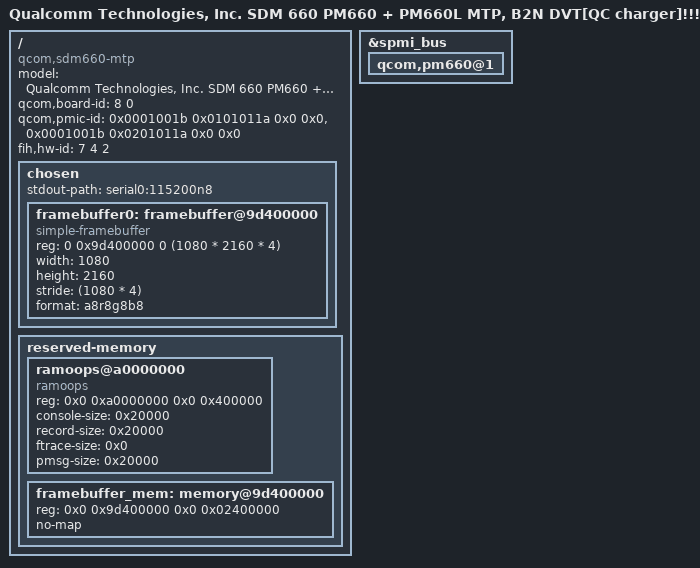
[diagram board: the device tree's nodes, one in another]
/* Copyright (c) 2016-2017, The Linux Foundation. All rights reserved.
 *
 * This program is free software; you can redistribute it and/or modify
 * it under the terms of the GNU General Public License version 2 and
 * only version 2 as published by the Free Software Foundation.
 *
 * This program is distributed in the hope that it will be useful,
 * but WITHOUT ANY WARRANTY; without even the implied warranty of
 * MERCHANTABILITY or FITNESS FOR A PARTICULAR PURPOSE.  See the
 * GNU General Public License for more details.
 */


/dts-v1/;

#include "sdm660.dtsi"
#include "sdm660-mtp.dtsi"
#include "sdm660-internal-codec-b2n.dtsi"
#include "fih/nokia/b2n-DVT-660-QC.dtsi"

/ {
	model = "Qualcomm Technologies, Inc. SDM 660 PM660 + PM660L MTP, B2N DVT[QC charger]!!!!!!!!!!!!!!!!!!!";
	compatible = "qcom,sdm660-mtp", "qcom,sdm660", "qcom,mtp";
	qcom,board-id = <8 0>;
	qcom,pmic-id = <0x0001001b 0x0101011a 0x0 0x0>,
			<0x0001001b 0x0201011a 0x0 0x0>;
	fih,hw-id = <7 4 2>;
	
	chosen {
		#address-cells = <2>;
		#size-cells = <2>;
		ranges;

		stdout-path = "serial0:115200n8";

		framebuffer0: framebuffer@9d400000 {
			compatible = "simple-framebuffer";
			reg = <0 0x9d400000 0 (1080 * 2160 * 4)>;
			width = <1080>;
			height = <2160>;
			stride = <(1080 * 4)>;
			format = "a8r8g8b8";
		};
	};

	reserved-memory {
		#address-cells = <2>;
		#size-cells = <2>;
		ranges;

		ramoops@a0000000 {
			compatible = "ramoops";
			reg = <0x0 0xa0000000 0x0 0x400000>;
			console-size = <0x20000>;
			record-size = <0x20000>;
			ftrace-size = <0x0>;
			pmsg-size = <0x20000>;
		};

		framebuffer_mem: memory@9d400000 {
			reg = <0x0 0x9d400000 0x0 0x02400000>;
			no-map;
		};

	};
};
&spmi_bus {

qcom,pm660@1 {
			/delete-node/ qcom,haptic@c000 ;
		};
};
